# PIC32MZ2048EFM144 register map
Registers are 32-bit, access not given, reset 0x0 unless marked. A register's access mark holds for its fields unless they carry their own. Offsets are from the block's base; [hi:lo] are bit positions; 'fields as' and 'values as' point back to an identical list.

## I2C1 — I2C1 peripheral
Base 0xBF820000
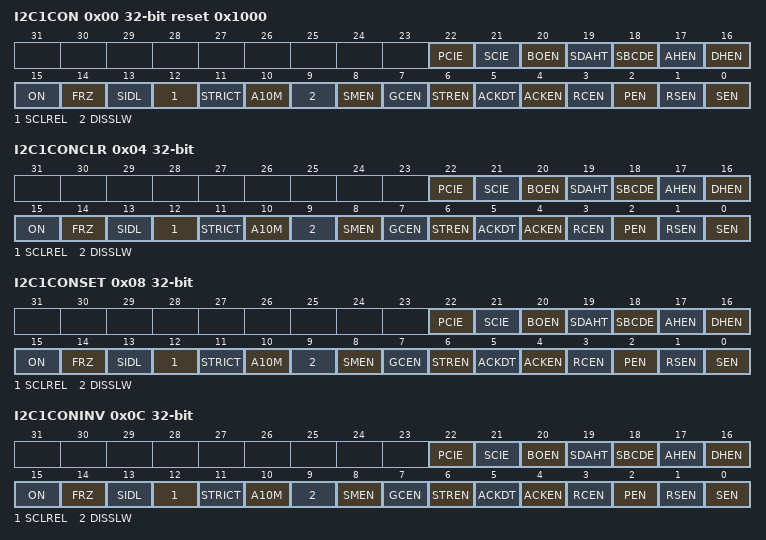
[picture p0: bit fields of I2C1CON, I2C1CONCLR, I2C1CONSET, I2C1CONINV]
0x00 I2C1CON reset 0x1000
  [22] PCIE, [21] SCIE, [20] BOEN, [19] SDAHT, [18] SBCDE, [17] AHEN, [16] DHEN, [15] ON, [14] FRZ, [13] SIDL, [12] SCLREL, [11] STRICT, [10] A10M, [9] DISSLW, [8] SMEN, [7] GCEN, [6] STREN, [5] ACKDT, [4] ACKEN, [3] RCEN, [2] PEN, [1] RSEN, [0] SEN
0x04 I2C1CONCLR
  fields as I2C1CON
0x08 I2C1CONSET
  fields as I2C1CON
0x0C I2C1CONINV
  fields as I2C1CON
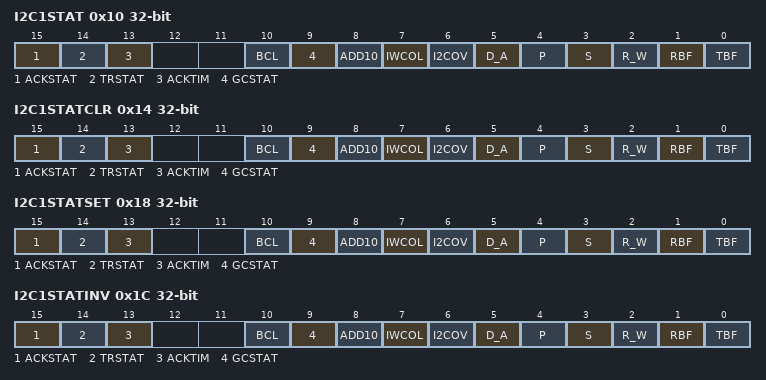
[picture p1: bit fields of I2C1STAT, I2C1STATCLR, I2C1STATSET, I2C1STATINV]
0x10 I2C1STAT
  [15] ACKSTAT, [14] TRSTAT, [13] ACKTIM, [10] BCL, [9] GCSTAT, [8] ADD10, [7] IWCOL, [6] I2COV, [5] D_A, [4] P, [3] S, [2] R_W, [1] RBF, [0] TBF
0x14 I2C1STATCLR
  fields as I2C1STAT
0x18 I2C1STATSET
  fields as I2C1STAT
0x1C I2C1STATINV
  fields as I2C1STAT
0x20 I2C1ADD
  [9:0] I2CADD
0x24 I2C1ADDCLR
  [9:0] I2CADD
0x28 I2C1ADDSET
  [9:0] I2CADD
0x2C I2C1ADDINV
  [9:0] I2CADD
0x30 I2C1MSK
  [9:0] I2CMSK
0x34 I2C1MSKCLR
  [9:0] I2CMSK
0x38 I2C1MSKSET
  [9:0] I2CMSK
0x3C I2C1MSKINV
  [9:0] I2CMSK
0x40 I2C1BRG
  [15:0] I2CBRG
0x44 I2C1BRGCLR
  [15:0] I2CBRG
0x48 I2C1BRGSET
  [15:0] I2CBRG
0x4C I2C1BRGINV
  [15:0] I2CBRG
0x50 I2C1TRN reset 0xFF
  [7:0] I2CTRN
0x54 I2C1TRNCLR
  [7:0] I2CTRN
0x58 I2C1TRNSET
  [7:0] I2CTRN
0x5C I2C1TRNINV
  [7:0] I2CTRN
0x60 I2C1RCV
  [7:0] I2CRCV
0x64 I2C1RCVCLR
  [7:0] I2CRCV
0x68 I2C1RCVSET
  [7:0] I2CRCV
0x6C I2C1RCVINV
  [7:0] I2CRCV

## I2C2 — I2C2 peripheral
Base 0xBF820200
Registers as I2C1 (with I2C1 read as I2C2).

## I2C3 — I2C3 peripheral
Base 0xBF820400
Registers as I2C1 (with I2C1 read as I2C3).

## I2C4 — I2C4 peripheral
Base 0xBF820600
Registers as I2C1 (with I2C1 read as I2C4).

## I2C5 — I2C5 peripheral
Base 0xBF820800
Registers as I2C1 (with I2C1 read as I2C5).

## SPI1 — SPI1 peripheral
Base 0xBF821000
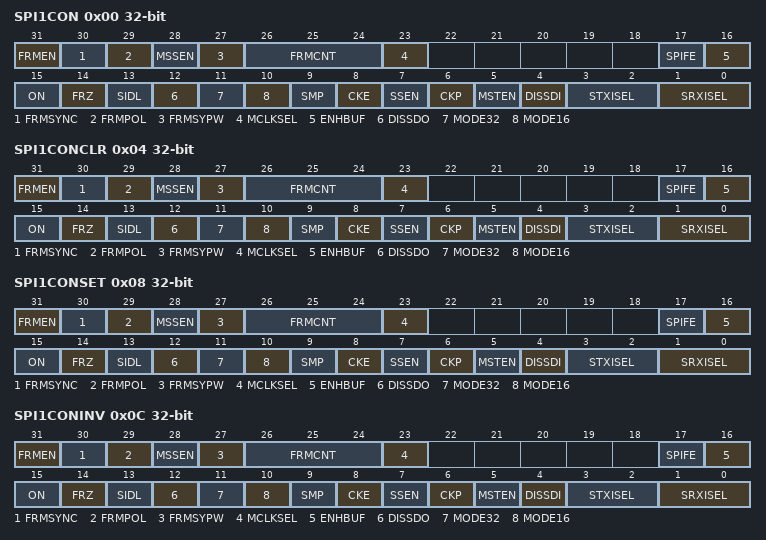
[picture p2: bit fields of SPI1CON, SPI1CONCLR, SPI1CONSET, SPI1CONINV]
0x00 SPI1CON
  [31] FRMEN, [30] FRMSYNC, [29] FRMPOL, [28] MSSEN, [27] FRMSYPW, [26:24] FRMCNT, [23] MCLKSEL, [17] SPIFE, [16] ENHBUF, [15] ON, [14] FRZ, [13] SIDL, [12] DISSDO, [11] MODE32, [10] MODE16, [9] SMP, [8] CKE, [7] SSEN, [6] CKP, [5] MSTEN, [4] DISSDI, [3:2] STXISEL, [1:0] SRXISEL
0x04 SPI1CONCLR
  fields as SPI1CON
0x08 SPI1CONSET
  fields as SPI1CON
0x0C SPI1CONINV
  fields as SPI1CON
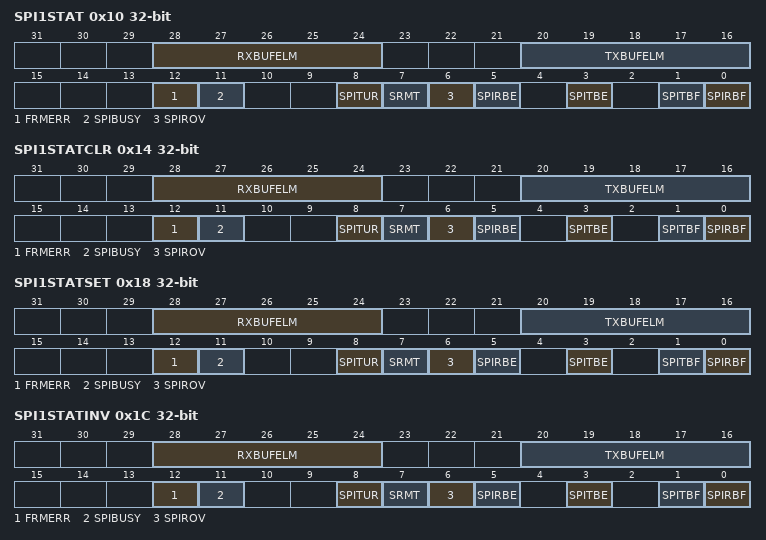
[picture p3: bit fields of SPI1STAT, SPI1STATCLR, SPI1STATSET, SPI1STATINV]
0x10 SPI1STAT
  [28:24] RXBUFELM, [20:16] TXBUFELM, [12] FRMERR, [11] SPIBUSY, [8] SPITUR, [7] SRMT, [6] SPIROV, [5] SPIRBE, [3] SPITBE, [1] SPITBF, [0] SPIRBF
0x14 SPI1STATCLR
  fields as SPI1STAT
0x18 SPI1STATSET
  fields as SPI1STAT
0x1C SPI1STATINV
  fields as SPI1STAT
0x20 SPI1BUF
0x30 SPI1BRG
  [12:0] SPI1BRG
0x34 SPI1BRGCLR
  [12:0] SPI1BRG
0x38 SPI1BRGSET
  [12:0] SPI1BRG
0x3C SPI1BRGINV
  [12:0] SPI1BRG
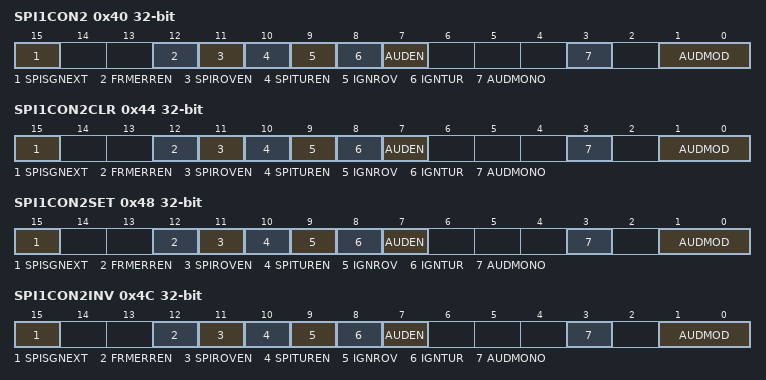
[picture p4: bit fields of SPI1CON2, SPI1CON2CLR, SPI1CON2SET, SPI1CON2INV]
0x40 SPI1CON2
  [15] SPISGNEXT, [12] FRMERREN, [11] SPIROVEN, [10] SPITUREN, [9] IGNROV, [8] IGNTUR, [7] AUDEN, [3] AUDMONO, [1:0] AUDMOD
0x44 SPI1CON2CLR
  fields as SPI1CON2
0x48 SPI1CON2SET
  fields as SPI1CON2
0x4C SPI1CON2INV
  fields as SPI1CON2

## SPI2 — SPI2 peripheral
Base 0xBF821200
Registers as SPI1 (with SPI1 read as SPI2).

## SPI3 — SPI3 peripheral
Base 0xBF821400
Registers as SPI1 (with SPI1 read as SPI3).

## SPI4 — SPI4 peripheral
Base 0xBF821600
Registers as SPI1 (with SPI1 read as SPI4).

## SPI5 — SPI5 peripheral
Base 0xBF821800
Registers as SPI1 (with SPI1 read as SPI5).

## SPI6 — SPI6 peripheral
Base 0xBF821A00
Registers as SPI1 (with SPI1 read as SPI6).

## UART1 — UART1 peripheral
Base 0xBF822000
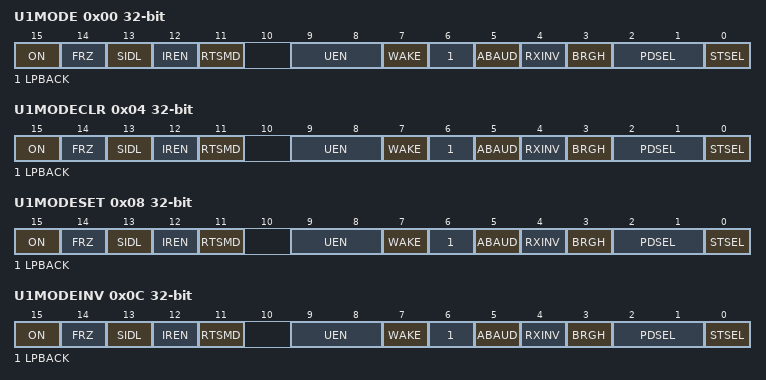
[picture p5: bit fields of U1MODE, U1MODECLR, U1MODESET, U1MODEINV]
0x00 U1MODE
  [15] ON, [14] FRZ, [13] SIDL, [12] IREN, [11] RTSMD, [9:8] UEN, [7] WAKE, [6] LPBACK, [5] ABAUD, [4] RXINV, [3] BRGH, [2:1] PDSEL, [0] STSEL
0x04 U1MODECLR
  fields as U1MODE
0x08 U1MODESET
  fields as U1MODE
0x0C U1MODEINV
  fields as U1MODE
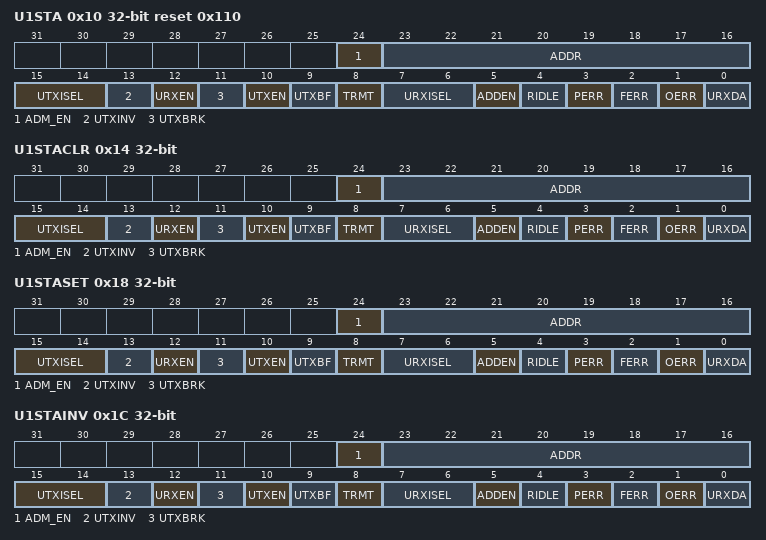
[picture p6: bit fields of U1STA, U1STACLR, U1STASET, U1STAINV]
0x10 U1STA reset 0x110
  [24] ADM_EN, [23:16] ADDR, [15:14] UTXISEL, [13] UTXINV, [12] URXEN, [11] UTXBRK, [10] UTXEN, [9] UTXBF, [8] TRMT, [7:6] URXISEL, [5] ADDEN, [4] RIDLE, [3] PERR, [2] FERR, [1] OERR, [0] URXDA
0x14 U1STACLR
  fields as U1STA
0x18 U1STASET
  fields as U1STA
0x1C U1STAINV
  fields as U1STA
0x20 U1TXREG
  [8:0] U1TXREG
0x30 U1RXREG
  [8:0] U1RXREG
0x40 U1BRG
  [15:0] BRG
0x44 U1BRGCLR
  [15:0] BRG
0x48 U1BRGSET
  [15:0] BRG
0x4C U1BRGINV
  [15:0] BRG
